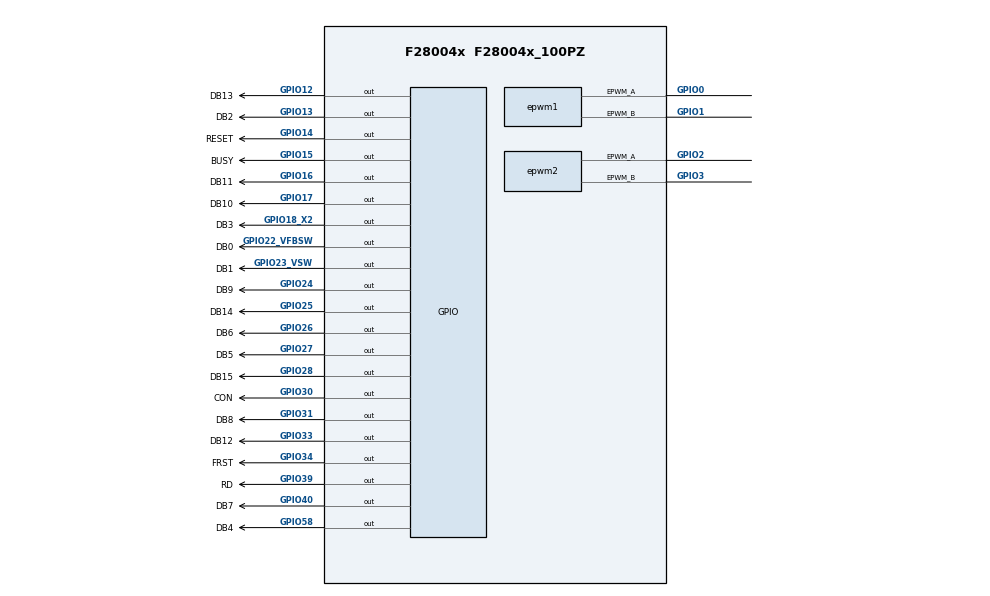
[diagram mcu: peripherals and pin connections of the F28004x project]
/**
 * @cliArgs --device "F28004x" --package "F28004x_100PZ" --part "F28004x_100PZ" --context "system" --product "C2000WARE@4.03.00.00"
 * @versions {"tool":"1.16.1+2960"}
 */

/**
 * Import the modules used in this configuration.
 */
const epwm       = scripting.addModule("/driverlib/epwm.js", {}, false);
const epwm1      = epwm.addInstance();
const epwm2      = epwm.addInstance();
const epwm3      = epwm.addInstance();
const gpio       = scripting.addModule("/driverlib/gpio.js", {}, false);
const gpio1      = gpio.addInstance();
const gpio2      = gpio.addInstance();
const gpio3      = gpio.addInstance();
const gpio4      = gpio.addInstance();
const gpio5      = gpio.addInstance();
const gpio6      = gpio.addInstance();
const gpio7      = gpio.addInstance();
const gpio8      = gpio.addInstance();
const gpio9      = gpio.addInstance();
const gpio10     = gpio.addInstance();
const gpio11     = gpio.addInstance();
const gpio12     = gpio.addInstance();
const gpio13     = gpio.addInstance();
const gpio14     = gpio.addInstance();
const gpio15     = gpio.addInstance();
const gpio16     = gpio.addInstance();
const gpio17     = gpio.addInstance();
const gpio18     = gpio.addInstance();
const gpio19     = gpio.addInstance();
const gpio20     = gpio.addInstance();
const gpio21     = gpio.addInstance();
const inputxbar  = scripting.addModule("/driverlib/inputxbar.js", {}, false);
const inputxbar1 = inputxbar.addInstance();

/**
 * Write custom configuration values to the imported modules.
 */
const multiplier2         = system.clockTree["PLL_IMULT"];
multiplier2.multiplyValue = 10;

epwm1.epwmTimebase_counterMode                                   = "EPWM_COUNTER_MODE_UP_DOWN";
epwm1.epwmTimebase_hsClockDiv                                    = "EPWM_HSCLOCK_DIVIDER_1";
epwm1.epwmActionQualifier_EPWM_AQ_OUTPUT_A_shadowMode            = true;
epwm1.epwmDeadband_enableRED                                     = true;
epwm1.epwmDeadband_enableFED                                     = true;
epwm1.epwmDeadband_delayRED                                      = 50;
epwm1.epwmDeadband_delayFED                                      = 50;
epwm1.epwmActionQualifier_EPWM_AQ_OUTPUT_A_ON_TIMEBASE_ZERO      = "EPWM_AQ_OUTPUT_HIGH";
epwm1.epwmActionQualifier_EPWM_AQ_OUTPUT_A_ON_TIMEBASE_UP_CMPA   = "EPWM_AQ_OUTPUT_LOW";
epwm1.epwmActionQualifier_EPWM_AQ_OUTPUT_A_ON_TIMEBASE_DOWN_CMPA = "EPWM_AQ_OUTPUT_HIGH";
epwm1.epwmActionQualifier_EPWM_AQ_OUTPUT_B_ON_TIMEBASE_UP_CMPB   = "EPWM_AQ_OUTPUT_HIGH";
epwm1.epwmActionQualifier_EPWM_AQ_OUTPUT_B_ON_TIMEBASE_DOWN_CMPB = "EPWM_AQ_OUTPUT_LOW";
epwm1.epwmEventTrigger_enableInterrupt                           = true;
epwm1.epwmEventTrigger_interruptSource                           = "EPWM_INT_TBCTR_ZERO";
epwm1.$name                                                      = "myEPWM1";
epwm1.epwmTimebase_period                                        = 2500;
epwm1.epwmEventTrigger_interruptEventCount                       = "1";
epwm1.epwm.$assign                                               = "EPWM1";
epwm1.epwm.epwm_aPin.$assign                                     = "GPIO0";
epwm1.epwm.epwm_bPin.$assign                                     = "GPIO1";

epwm2.epwmTimebase_period                                        = 2499;
epwm2.epwmTimebase_counterValue                                  = 500;
epwm2.epwmTimebase_counterMode                                   = "EPWM_COUNTER_MODE_UP_DOWN";
epwm2.epwmActionQualifier_EPWM_AQ_OUTPUT_A_shadowMode            = true;
epwm2.epwmActionQualifier_EPWM_AQ_OUTPUT_B_shadowMode            = true;
epwm2.epwmDeadband_enableRED                                     = true;
epwm2.epwmDeadband_enableFED                                     = true;
epwm2.epwmDeadband_redShadowMode                                 = true;
epwm2.epwmDeadband_fedShadowMode                                 = true;
epwm2.epwmDeadband_outputSwapOutA                                = true;
epwm2.epwmDeadband_outputSwapOutB                                = true;
epwm2.epwmDeadband_delayRED                                      = 50;
epwm2.epwmDeadband_delayFED                                      = 50;
epwm2.epwmActionQualifier_EPWM_AQ_OUTPUT_A_ON_TIMEBASE_ZERO      = "EPWM_AQ_OUTPUT_HIGH";
epwm2.epwmActionQualifier_EPWM_AQ_OUTPUT_A_ON_TIMEBASE_UP_CMPA   = "EPWM_AQ_OUTPUT_LOW";
epwm2.epwmActionQualifier_EPWM_AQ_OUTPUT_A_ON_TIMEBASE_DOWN_CMPA = "EPWM_AQ_OUTPUT_HIGH";
epwm2.epwmActionQualifier_EPWM_AQ_OUTPUT_B_ON_TIMEBASE_UP_CMPB   = "EPWM_AQ_OUTPUT_HIGH";
epwm2.epwmActionQualifier_EPWM_AQ_OUTPUT_B_ON_TIMEBASE_DOWN_CMPB = "EPWM_AQ_OUTPUT_LOW";
epwm2.epwmEventTrigger_enableInterrupt                           = true;
epwm2.epwmEventTrigger_interruptEventCount                       = "1";
epwm2.epwmEventTrigger_interruptSource                           = "EPWM_INT_TBCTR_ZERO";
epwm2.$name                                                      = "myEPWM2";
epwm2.epwm.$assign                                               = "EPWM2";
epwm2.epwm.epwm_aPin.$assign                                     = "GPIO2";
epwm2.epwm.epwm_bPin.$assign                                     = "GPIO3";

epwm3.epwmTimebase_hsClockDiv                                    = "EPWM_HSCLOCK_DIVIDER_1";
epwm3.epwmTimebase_period                                        = 2499;
epwm3.epwmTimebase_counterValue                                  = 500;
epwm3.epwmCounterCompare_cmpA                                    = 250;
epwm3.epwmActionQualifier_EPWM_AQ_OUTPUT_A_shadowMode            = true;
epwm3.epwmDeadband_enableRED                                     = true;
epwm3.epwmDeadband_enableFED                                     = true;
epwm3.epwmDeadband_redShadowMode                                 = true;
epwm3.epwmDeadband_fedShadowMode                                 = true;
epwm3.epwmDeadband_inputFED                                      = "EPWM_DB_INPUT_EPWMB";
epwm3.epwmDeadband_delayRED                                      = 50;
epwm3.epwmDeadband_delayFED                                      = 50;
epwm3.epwmActionQualifier_EPWM_AQ_OUTPUT_A_ON_TIMEBASE_ZERO      = "EPWM_AQ_OUTPUT_HIGH";
epwm3.epwmActionQualifier_EPWM_AQ_OUTPUT_A_ON_TIMEBASE_UP_CMPA   = "EPWM_AQ_OUTPUT_LOW";
epwm3.epwmActionQualifier_EPWM_AQ_OUTPUT_A_ON_TIMEBASE_DOWN_CMPA = "EPWM_AQ_OUTPUT_HIGH";
epwm3.epwmActionQualifier_EPWM_AQ_OUTPUT_B_ON_TIMEBASE_UP_CMPB   = "EPWM_AQ_OUTPUT_HIGH";
epwm3.epwmActionQualifier_EPWM_AQ_OUTPUT_B_ON_TIMEBASE_DOWN_CMPB = "EPWM_AQ_OUTPUT_LOW";
epwm3.$name                                                      = "myEPWM3";

gpio1.$name             = "RD";
gpio1.writeInitialValue = true;
gpio1.initialValue      = 1;
gpio1.gpioPin.$assign   = "GPIO39";

gpio2.$name           = "CON";
gpio2.gpioPin.$assign = "GPIO30";

gpio3.$name             = "RESET";
gpio3.writeInitialValue = true;
gpio3.gpioPin.$assign   = "GPIO14";

gpio4.$name           = "BUSY";
gpio4.gpioPin.$assign = "GPIO15";

gpio5.$name           = "FRST";
gpio5.gpioPin.$assign = "GPIO34";

gpio6.$name           = "DB0";
gpio6.gpioPin.$assign = "GPIO22_VFBSW";

gpio7.$name           = "DB1";
gpio7.gpioPin.$assign = "GPIO23_VSW";

gpio8.$name           = "DB2";
gpio8.gpioPin.$assign = "GPIO13";

gpio9.$name           = "DB3";
gpio9.gpioPin.$assign = "GPIO18_X2";

gpio10.$name           = "DB4";
gpio10.gpioPin.$assign = "GPIO58";

gpio11.$name           = "DB5";
gpio11.gpioPin.$assign = "GPIO27";

gpio12.$name           = "DB6";
gpio12.gpioPin.$assign = "GPIO26";

gpio13.$name           = "DB7";
gpio13.gpioPin.$assign = "GPIO40";

gpio14.$name           = "DB8";
gpio14.gpioPin.$assign = "GPIO31";

gpio15.$name           = "DB9";
gpio15.gpioPin.$assign = "GPIO24";

gpio16.$name           = "DB10";
gpio16.gpioPin.$assign = "GPIO17";

gpio17.$name           = "DB11";
gpio17.gpioPin.$assign = "GPIO16";

gpio18.$name           = "DB12";
gpio18.gpioPin.$assign = "GPIO33";

gpio19.$name           = "DB13";
gpio19.gpioPin.$assign = "GPIO12";

gpio20.$name           = "DB14";
gpio20.gpioPin.$assign = "GPIO25";

gpio21.$name           = "DB15";
gpio21.gpioPin.$assign = "GPIO28";

inputxbar1.$name = "myINPUTXBAR0";

/**
 * Pinmux solution for unlocked pins/peripherals. This ensures that minor changes to the automatic solver in a future
 * version of the tool will not impact the pinmux you originally saw.  These lines can be completely deleted in order to
 * re-solve from scratch.
 */
epwm3.epwm.$suggestSolution           = "EPWM3";
epwm3.epwm.epwm_aPin.$suggestSolution = "GPIO4";
epwm3.epwm.epwm_bPin.$suggestSolution = "GPIO5";
